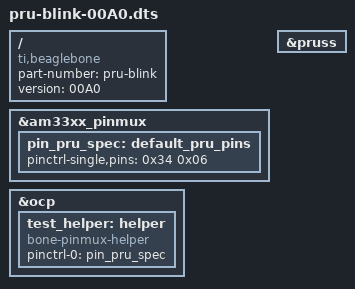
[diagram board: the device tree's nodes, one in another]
/dts-v1/;  
/plugin/; 

/{
	compatible = "ti,beaglebone", "ti,beaglebone-green", "ti,beaglebone-black";  
	part-number = "pru-blink";  
	version = "00A0";
	
	fragment@0 {
		target = <&am33xx_pinmux>;
		__overlay__ {
			pin_pru_spec: default_pru_pins {
				pinctrl-single,pins = <
					0x34 0x06 /* P8_11 */
				>;
			};
		};
	};

	fragment@1 {
		target = <&ocp>;
		__overlay__ {
			test_helper: helper {
				compatible = "bone-pinmux-helper";
				pinctrl-names = "default";
				pinctrl-0 = <&pin_pru_spec>;
				status = "okay";
			};
		};
	};
	
   
	fragment@2 {
		target = <&pruss>;
		__overlay__ {
			status = "okay";
		};
	};

};
